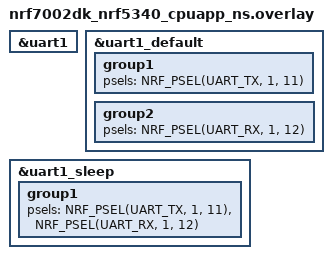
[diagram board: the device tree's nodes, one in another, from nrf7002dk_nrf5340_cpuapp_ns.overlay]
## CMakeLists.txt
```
cmake_minimum_required(VERSION 3.20.0)
find_package(Zephyr REQUIRED HINTS $ENV{ZEPHYR_BASE})

project(uart_tx)

target_sources(app PRIVATE src/main.c)
target_sources(app PRIVATE src/uart_driver.c)
```

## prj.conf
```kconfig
CONFIG_PRINTK=y
CONFIG_SERIAL=y
CONFIG_LOG=y
CONFIG_UART_ASYNC_API=y
CONFIG_CONSOLE=y
CONFIG_PINCTRL=y
CONFIG_GPIO=y
```

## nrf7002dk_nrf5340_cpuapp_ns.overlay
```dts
&uart1 {
    status = "disabled";
};

&uart1 {
    status = "okay";
};

&uart1_default {
    group1 {
        psels = <NRF_PSEL(UART_TX, 1, 11)>;
    };
};

&uart1_default {
    group2 {
        psels = <NRF_PSEL(UART_RX, 1, 12)>;
    };
};

&uart1_sleep {
    group1 {
        psels = <NRF_PSEL(UART_TX, 1, 11)>, <NRF_PSEL(UART_RX, 1, 12)>;
    };
};

&uart1_sleep {
    group1 {
        psels = <NRF_PSEL(UART_TX, 1, 11)>, <NRF_PSEL(UART_RX, 1, 12)>;
    };
};
```

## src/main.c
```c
#include <zephyr/kernel.h>
#include "uart_driver.h"
#include <zephyr/drivers/gpio.h>
#include "zephyr/drivers/uart.h"

int main(void)
{
        uart_transmit();
        printk("uart_tx exited\r\n\n");
        return 0;
}
```

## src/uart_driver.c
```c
#include <zephyr/kernel.h>
#include <zephyr/drivers/gpio.h>
#include "zephyr/drivers/uart.h"
#include "uart_driver.h"

const struct device *uart = DEVICE_DT_GET(DT_NODELABEL(uart1));

static uint8_t tx_buf[] = {"NO MORE WORK FROM HOME\r\n"};
static uint8_t rx_buf[50] = {0};

const struct uart_config uart_cfg = {
    .baudrate = 115200,
    .parity = UART_CFG_PARITY_NONE,
    .stop_bits = UART_CFG_STOP_BITS_1,
    .data_bits = UART_CFG_DATA_BITS_8,
    .flow_ctrl = UART_CFG_FLOW_CTRL_NONE};

void uart_transmit()
{
    // k_msleep(1000);
    // static uint8_t tx_buf[] = {"Hello! Welcome to IndieSemiC Pvt Ltd!!\r\n"};

    if (!device_is_ready(uart))
    {
        return 0;
    }
    uart_tx(uart, tx_buf, sizeof(tx_buf), SYS_FOREVER_MS);
    k_msleep(500);
    printk("Data Transmitted....\r\n");
}

static void uart_cb(const struct device *dev, struct uart_event *evt, void *user_data)
{
    switch (evt->type)
    {
    case UART_RX_RDY:
        printf("rx rdy \n");
        printk("data received = %s \n", evt->data.rx_buf);
        break;

    case UART_RX_BUF_REQUEST:
        break;

    case UART_RX_DISABLED:
        printf("rx disabled \n");
        uart_rx_enable(dev, rx_buf, sizeof(rx_buf), SYS_FOREVER_US);
        break;

    default:
        break;
    }
}

void uart_receiver()
{
    printk("Hi!\r\n");
    if (!device_is_ready(uart))
    {
        return;
    }

    uart_callback_set(uart, uart_cb, NULL);
    uart_rx_enable(uart, rx_buf, sizeof(rx_buf), SYS_FOREVER_US);
    // uart_tx(uart, rx_buf, sizeof(rx_buf), SYS_FOREVER_US);
/* 
    while (1)
    {
        k_msleep(1000);
    } */
    return 0;
}
```
